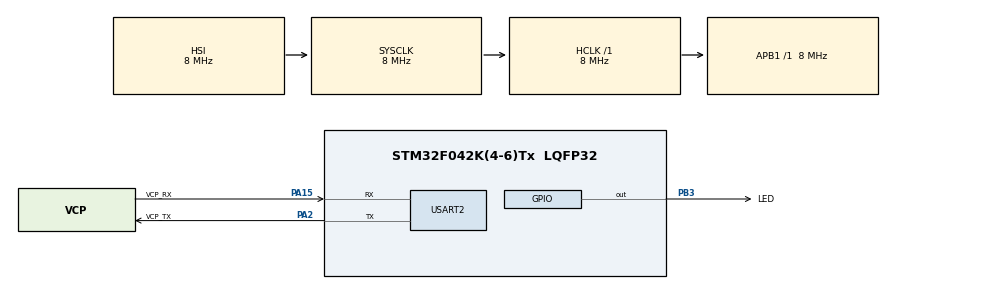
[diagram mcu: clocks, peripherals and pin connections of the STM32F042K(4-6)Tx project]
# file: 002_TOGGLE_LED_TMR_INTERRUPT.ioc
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Mcu.Family=STM32F0
Mcu.Name=STM32F042K(4-6)Tx
Mcu.Package=LQFP32
NVIC.TIM3_IRQn=true\:0\:0\:false\:false\:true\:true\:true\:true
PA13.GPIO_Label=SWDIO
PA13.Mode=Serial_Wire
PA13.Signal=SYS_SWDIO
PA14.GPIO_Label=SWCLK
PA14.Mode=Serial_Wire
PA14.Signal=SYS_SWCLK
PA15.GPIO_Label=VCP_RX
PA15.Mode=Asynchronous
PA15.Signal=USART2_RX
PA2.GPIO_Label=VCP_TX
PA2.Mode=Asynchronous
PA2.Signal=USART2_TX
PB3.GPIO_Label=LED
PB3.Signal=GPIO_Output
PF0-OSC_IN.GPIO_Label=MCO
PF0-OSC_IN.Mode=HSE-External-Clock-Source
PF0-OSC_IN.Signal=RCC_OSC_IN
ProjectManager.HeapSize=0x200
ProjectManager.StackSize=0x400
ProjectManager.TargetToolchain=STM32CubeIDE
RCC.AHBFreq_Value=8000000
RCC.APB1Freq_Value=8000000
RCC.APB1TimFreq_Value=8000000
RCC.HCLKFreq_Value=8000000
RCC.SYSCLKFreq_VALUE=8000000
TIM3.ClockDivision=TIM_CLOCKDIVISION_DIV1
TIM3.Period=249
TIM3.Prescaler=7999
USART2.VirtualMode-Asynchronous=VM_ASYNC
VP_TIM3_VS_ClockSourceINT.Mode=Internal
board=NUCLEO-F042K6

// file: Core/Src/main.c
/* USER CODE BEGIN Header */
/**
  ******************************************************************************
  * @file           : main.c
  * @brief          : Main program body
  ******************************************************************************
  * @attention
  *
  * Copyright (c) 2023 STMicroelectronics.
  * All rights reserved.
  *
  * This software is licensed under terms that can be found in the LICENSE file
  * in the root directory of this software component.
  * If no LICENSE file comes with this software, it is provided AS-IS.
  *
  ******************************************************************************
  */
/* USER CODE END Header */
#include "main.h"

TIM_HandleTypeDef htim3;

UART_HandleTypeDef huart2;

void SystemClock_Config(void);
static void MX_GPIO_Init(void);
static void MX_USART2_UART_Init(void);
static void MX_TIM3_Init(void);

int main(void)
{

  /* MCU Configuration--------------------------------------------------------*/

  /* Reset of all peripherals, Initializes the Flash interface and the Systick. */
  HAL_Init();

  /* Configure the system clock */
  SystemClock_Config();

  /* Initialize all configured peripherals */
  MX_GPIO_Init();
  MX_USART2_UART_Init();
  MX_TIM3_Init();

  /* Infinite loop */
  while (1)
  {

  }
}

void SystemClock_Config(void)
{
  RCC_OscInitTypeDef RCC_OscInitStruct = {0};
  RCC_ClkInitTypeDef RCC_ClkInitStruct = {0};

  /** Initializes the RCC Oscillators according to the specified parameters
  * in the RCC_OscInitTypeDef structure.
  */
  RCC_OscInitStruct.OscillatorType = RCC_OSCILLATORTYPE_HSI;
  RCC_OscInitStruct.HSIState = RCC_HSI_ON;
  RCC_OscInitStruct.HSICalibrationValue = RCC_HSICALIBRATION_DEFAULT;
  RCC_OscInitStruct.PLL.PLLState = RCC_PLL_NONE;
  if (HAL_RCC_OscConfig(&RCC_OscInitStruct) != HAL_OK)
  {
    Error_Handler();
  }

  /** Initializes the CPU, AHB and APB buses clocks
  */
  RCC_ClkInitStruct.ClockType = RCC_CLOCKTYPE_HCLK|RCC_CLOCKTYPE_SYSCLK
                              |RCC_CLOCKTYPE_PCLK1;
  RCC_ClkInitStruct.SYSCLKSource = RCC_SYSCLKSOURCE_HSI;
  RCC_ClkInitStruct.AHBCLKDivider = RCC_SYSCLK_DIV1;
  RCC_ClkInitStruct.APB1CLKDivider = RCC_HCLK_DIV1;

  if (HAL_RCC_ClockConfig(&RCC_ClkInitStruct, FLASH_LATENCY_0) != HAL_OK)
  {
    Error_Handler();
  }
}

static void MX_TIM3_Init(void)
{

  TIM_ClockConfigTypeDef sClockSourceConfig = {0};
  TIM_MasterConfigTypeDef sMasterConfig = {0};

  htim3.Instance = TIM3;
  htim3.Init.Prescaler = 7999;
  htim3.Init.CounterMode = TIM_COUNTERMODE_UP;
  htim3.Init.Period = 249;
  htim3.Init.ClockDivision = TIM_CLOCKDIVISION_DIV1;
  htim3.Init.AutoReloadPreload = TIM_AUTORELOAD_PRELOAD_DISABLE;
  if (HAL_TIM_Base_Init(&htim3) != HAL_OK)
  {
    Error_Handler();
  }
  sClockSourceConfig.ClockSource = TIM_CLOCKSOURCE_INTERNAL;
  if (HAL_TIM_ConfigClockSource(&htim3, &sClockSourceConfig) != HAL_OK)
  {
    Error_Handler();
  }
  sMasterConfig.MasterOutputTrigger = TIM_TRGO_RESET;
  sMasterConfig.MasterSlaveMode = TIM_MASTERSLAVEMODE_DISABLE;
  if (HAL_TIMEx_MasterConfigSynchronization(&htim3, &sMasterConfig) != HAL_OK)
  {
    Error_Handler();
  }
  /* USER CODE BEGIN TIM3_Init 2 */
  HAL_TIM_Base_Start_IT(&htim3);
  HAL_NVIC_SetPriority(TIM3_IRQn, 0, 0);
  HAL_NVIC_EnableIRQ(TIM3_IRQn);

  /* USER CODE END TIM3_Init 2 */

}

static void MX_USART2_UART_Init(void)
{

  huart2.Instance = USART2;
  huart2.Init.BaudRate = 38400;
  huart2.Init.WordLength = UART_WORDLENGTH_8B;
  huart2.Init.StopBits = UART_STOPBITS_1;
  huart2.Init.Parity = UART_PARITY_NONE;
  huart2.Init.Mode = UART_MODE_TX_RX;
  huart2.Init.HwFlowCtl = UART_HWCONTROL_NONE;
  huart2.Init.OverSampling = UART_OVERSAMPLING_16;
  huart2.Init.OneBitSampling = UART_ONE_BIT_SAMPLE_DISABLE;
  huart2.AdvancedInit.AdvFeatureInit = UART_ADVFEATURE_NO_INIT;
  if (HAL_UART_Init(&huart2) != HAL_OK)
  {
    Error_Handler();
  }

}

static void MX_GPIO_Init(void)
{
  GPIO_InitTypeDef GPIO_InitStruct = {0};

  /* GPIO Ports Clock Enable */
  __HAL_RCC_GPIOF_CLK_ENABLE();
  __HAL_RCC_GPIOA_CLK_ENABLE();
  __HAL_RCC_GPIOB_CLK_ENABLE();

  /*Configure GPIO pin Output Level */
  HAL_GPIO_WritePin(LED_GPIO_Port, LED_Pin, GPIO_PIN_RESET);

  /*Configure GPIO pin : LED_Pin */
  GPIO_InitStruct.Pin = LED_Pin;
  GPIO_InitStruct.Mode = GPIO_MODE_OUTPUT_PP;
  GPIO_InitStruct.Pull = GPIO_NOPULL;
  GPIO_InitStruct.Speed = GPIO_SPEED_FREQ_LOW;
  HAL_GPIO_Init(LED_GPIO_Port, &GPIO_InitStruct);

}

/* USER CODE BEGIN 4 */
void HAL_TIM_PeriodElapsedCallback (TIM_HandleTypeDef * htim)
{
	/**@note
	 * this is a weak function from the HAL library.
	 * the interrupt handler sends the function back here
	 * See page 505 of STM32F0 HAL user manual (UM1785)*/

	if(htim == &htim3)
	{
		HAL_GPIO_TogglePin(LED_GPIO_Port, LED_Pin);
	}
}

/* USER CODE END 4 */

void Error_Handler(void)
{
  __disable_irq();
  while (1)
  {
  }
}
